# WBZ451 register map
Vendor: Microchip
Registers are 32-bit, read-write, reset 0x0 unless marked. A register's access mark holds for its fields unless they carry their own. Addresses are absolute, and some are shared; only a register's first bit layout is shown; [hi:lo] are bit positions; {n}, {i} and the like mark numbered series; 'fields as' and 'values as' point back to an identical list.

## SysTick
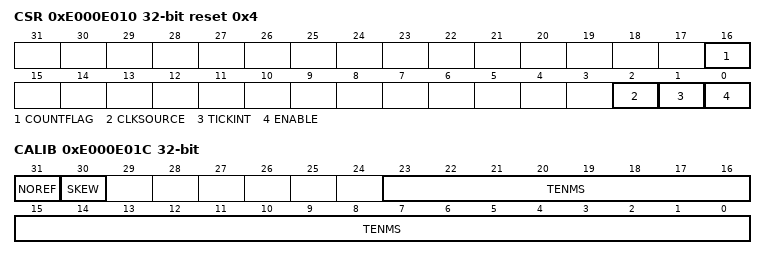
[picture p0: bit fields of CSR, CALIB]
0xE000E010 CSR reset 0x4
  [16] COUNTFLAG — Timer counted to 0 since last read of register
  [2] CLKSOURCE — Clock Source 0=external, 1=processor
    0=External clock; 1=Processor clock
  [1] TICKINT — SysTick Exception Request Enable
    0=Counting down to 0 does not assert the SysTick exception request; 1=Counting down to 0 asserts the SysTick exception request
  [0] ENABLE — SysTick Counter Enable
    0=Counter disabled; 1=Counter enabled
0xE000E014 RVR reset not defined
  [23:0] RELOAD — Value to load into the SysTick Current Value Register when the counter reaches 0
0xE000E018 CVR reset not defined
  [23:0] CURRENT — Current value at the time the register is accessed
0xE000E01C CALIB ro
  [31] NOREF — No Separate Reference Clock
    0=The reference clock is provided; 1=The reference clock is not provided
  [30] SKEW — TENMS is rounded from non-integer ratio
    0=10ms calibration value is exact; 1=10ms calibration value is inexact, because of the clock frequency
  [23:0] TENMS — Reload value to use for 10ms timing

## NVIC
{0xE000E100+4i} ISER{i} (i=0..4)
  [31:0] SETENA — Interrupt set enable bits
{0xE000E180+4i} ICER{i} (i=0..4)
  [31:0] CLRENA — Interrupt clear-enable bits
{0xE000E200+4i} ISPR{i} (i=0..4)
  [31:0] SETPEND — Interrupt set-pending bits
{0xE000E280+4i} ICPR{i} (i=0..4)
  [31:0] CLRPEND — Interrupt clear-pending bits
{0xE000E300+4i} IABR{i} (i=0..4)
  [31:0] ACTIVE — Interrupt active bits
{0xE000E400+i} IP{i} 8-bit (i=0..34)
  [2:0] PRI0 — Priority of interrupt n
0xE000EF00 STIR wo reset not defined
  [8:0] INTID — Interrupt ID to trigger

## MPU
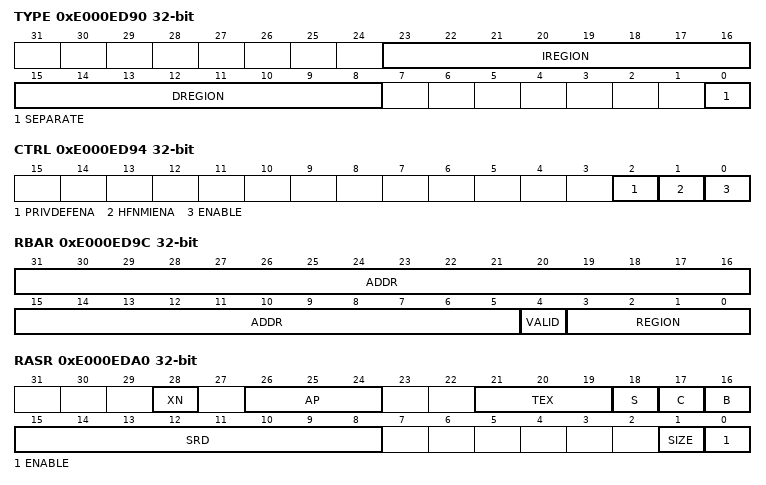
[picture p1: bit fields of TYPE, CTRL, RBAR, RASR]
0xE000ED90 TYPE ro reset not defined
  [23:16] IREGION — Number of Instruction Regions
  [15:8] DREGION — Number of Data Regions
  [0] SEPARATE — Separate instruction and Data Memory MapsRegions
0xE000ED94 CTRL reset not defined
  [2] PRIVDEFENA — Enables privileged software access to default memory map
  [1] HFNMIENA — Enable Hard Fault and NMI handlers
  [0] ENABLE — MPU Enable
0xE000ED98 RNR reset not defined
  [7:0] REGION — Region referenced by RBAR and RASR
0xE000ED9C RBAR reset not defined
  [31:5] ADDR — Region base address
  [4] VALID — Region number valid
  [3:0] REGION — Region number
0xE000EDA0 RASR reset not defined
  [28] XN — Execute Never Attribute
  [26:24] AP — Access Permission
  [21:19] TEX — TEX bit
  [18] S — Shareable bit
  [17] C — Cacheable bit
  [16] B — Bufferable bit
  [15:8] SRD — Sub-region disable
  [1] SIZE — Region Size
  [0] ENABLE — Region Enable
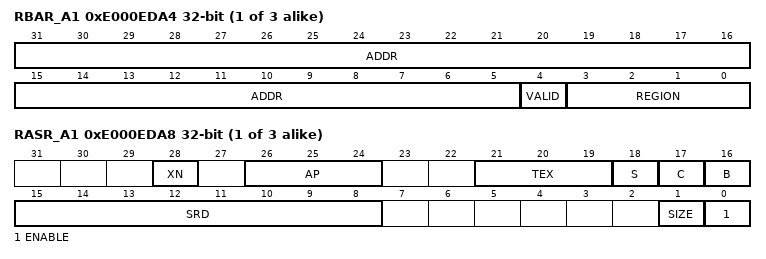
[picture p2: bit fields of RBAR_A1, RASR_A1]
{0xE000ED9C+8i} RBAR_A{i} reset not defined (i=1..3)
  fields as RBAR
{0xE000EDA0+8i} RASR_A{i} reset not defined (i=1..3)
  fields as RASR

## CoreDebug
0xE000EDF0 DHCSR reset not defined
  [25] S_RESET_ST, [24] S_RETIRE_ST, [19] S_LOCKUP, [18] S_SLEEP, [17] S_HALT, [31:16] DBGKEY, [5] C_SNAPSTALL, [3] C_MASKINTS, [2] C_STEP, [1] C_HALT, [0] C_DEBUGEN
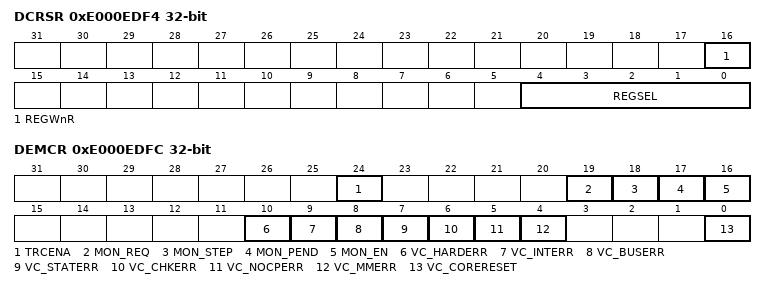
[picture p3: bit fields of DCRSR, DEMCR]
0xE000EDF4 DCRSR wo reset not defined
  [16] REGWnR, [4:0] REGSEL
0xE000EDF8 DCRDR reset not defined
0xE000EDFC DEMCR reset not defined
  [24] TRCENA, [19] MON_REQ, [18] MON_STEP, [17] MON_PEND, [16] MON_EN, [10] VC_HARDERR, [9] VC_INTERR, [8] VC_BUSERR, [7] VC_STATERR, [6] VC_CHKERR, [5] VC_NOCPERR, [4] VC_MMERR, [0] VC_CORERESET

## FPU
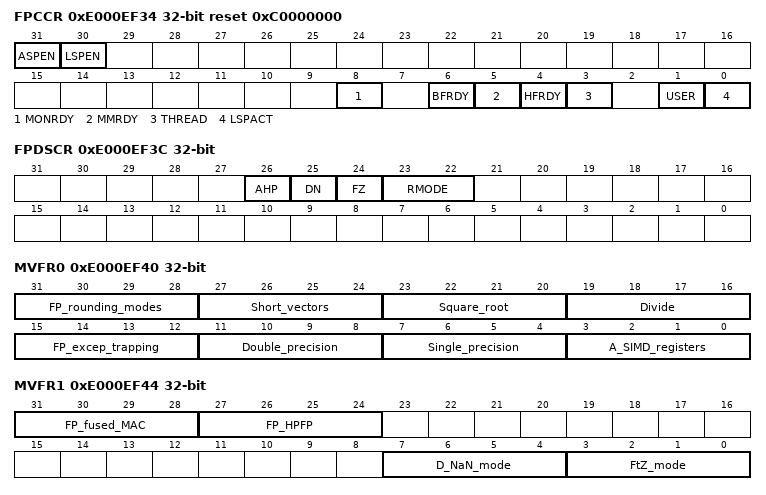
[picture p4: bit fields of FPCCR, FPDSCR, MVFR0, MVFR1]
0xE000EF34 FPCCR reset 0xC0000000
  [31] ASPEN, [30] LSPEN, [8] MONRDY, [6] BFRDY, [5] MMRDY, [4] HFRDY, [3] THREAD, [1] USER, [0] LSPACT
0xE000EF38 FPCAR reset not defined
  [31:3] ADDRESS — Address for FP registers in exception stack frame
0xE000EF3C FPDSCR
  [26] AHP — Default value for FPSCR.AHP
  [25] DN — Default value for FPSCR.DN
  [24] FZ — Default value for FPSCR.FZ
  [23:22] RMODE — Default value for FPSCR.RMODE
    0=RN (Round to Nearest); 1=RP (Round towards Positive Infinity); 2=RM (Round towards Negative Infinity); 3=RZ (Round towards Zero)
0xE000EF40 MVFR0 ro reset not defined
  [31:28] FP_rounding_modes, [27:24] Short_vectors, [23:20] Square_root, [19:16] Divide, [15:12] FP_excep_trapping, [11:8] Double_precision, [7:4] Single_precision, [3:0] A_SIMD_registers
0xE000EF44 MVFR1 ro reset not defined
  [31:28] FP_fused_MAC, [27:24] FP_HPFP, [7:4] D_NaN_mode, [3:0] FtZ_mode

## TPI
0xE0040000 SSPSR ro reset not defined
0xE0040004 CSPSR reset not defined
0xE0040010 ACPR reset not defined
  [12:0] PRESCALER
0xE00400F0 SPPR reset not defined
  [1:0] TXMODE
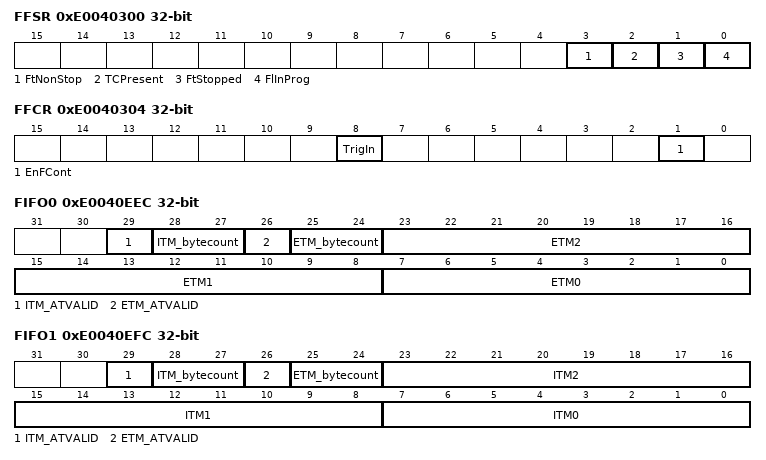
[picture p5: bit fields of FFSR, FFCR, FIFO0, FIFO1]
0xE0040300 FFSR ro reset not defined
  [3] FtNonStop, [2] TCPresent, [1] FtStopped, [0] FlInProg
0xE0040304 FFCR reset not defined
  [8] TrigIn, [1] EnFCont
0xE0040308 FSCR ro reset not defined
0xE0040EE8 TRIGGER ro reset not defined
  [0] TRIGGER
0xE0040EEC FIFO0 ro reset not defined
  [29] ITM_ATVALID, [28:27] ITM_bytecount, [26] ETM_ATVALID, [25:24] ETM_bytecount, [23:16] ETM2, [15:8] ETM1, [7:0] ETM0
0xE0040EF0 ITATBCTR2 ro reset not defined
  [0] ATREADY
0xE0040EF8 ITATBCTR0 ro reset not defined
  [0] ATREADY
0xE0040EFC FIFO1 ro reset not defined
  [29] ITM_ATVALID, [28:27] ITM_bytecount, [26] ETM_ATVALID, [25:24] ETM_bytecount, [23:16] ITM2, [15:8] ITM1, [7:0] ITM0
0xE0040F00 ITCTRL reset not defined
  [0] Mode
0xE0040FA0 CLAIMSET reset not defined
0xE0040FA4 CLAIMCLR reset not defined
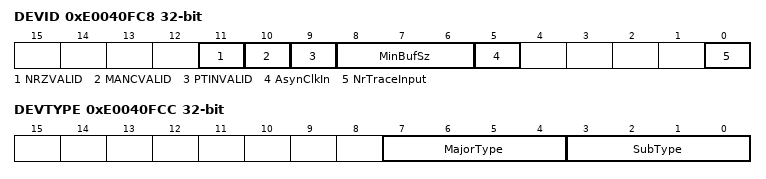
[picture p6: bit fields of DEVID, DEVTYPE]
0xE0040FC8 DEVID ro reset not defined
  [11] NRZVALID, [10] MANCVALID, [9] PTINVALID, [8:6] MinBufSz, [5] AsynClkIn, [0] NrTraceInput
0xE0040FCC DEVTYPE ro reset not defined
  [7:4] MajorType, [3:0] SubType

## ETM
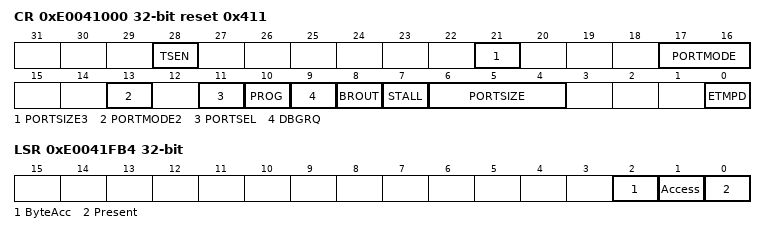
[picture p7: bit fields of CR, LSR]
0xE0041000 CR reset 0x411
  [28] TSEN — TimeStamp Enable
  [21] PORTSIZE3 — Port Size bit 3
  [17:16] PORTMODE — Port Mode bits 1:0
  [13] PORTMODE2 — Port Mode bit 2
  [11] PORTSEL — ETM Port Select
  [10] PROG — ETM Programming
  [9] DBGRQ — Debug Request Control
  [8] BROUT — Branch Output
  [7] STALL — Stall Processor
  [6:4] PORTSIZE — Port Size bits 2:0
  [0] ETMPD — ETM Power Down
0xE0041004 CCR ro reset 0x8C802000
0xE0041008 TRIGGER reset not defined
0xE0041010 SR reset not defined
0xE0041014 SCR ro reset 0x20D09
0xE0041020 TEEVR reset not defined
0xE0041024 TECR1 reset not defined
0xE0041028 FFLR reset not defined
0xE0041140 CNTRLDVR1 reset not defined
0xE00411E0 SYNCFR ro reset 0x400
0xE00411E4 IDR ro reset 0x4114F250
0xE00411E8 CCER ro reset 0x18541800
0xE00411F0 TESSEICR reset not defined
0xE00411F8 TSEVT reset not defined
0xE0041200 TRACEIDR
0xE0041208 IDR2 ro
0xE0041314 PDSR ro reset 0x1
0xE0041EE0 ITMISCIN ro reset not defined
0xE0041EE8 ITTRIGOUT wo reset not defined
0xE0041EF0 ITATBCTR2 ro reset not defined
0xE0041EF8 ITATBCTR0 wo reset not defined
0xE0041F00 ITCTRL
  [0] INTEGRATION
0xE0041FA0 CLAIMSET reset not defined
0xE0041FA4 CLAIMCLR reset not defined
0xE0041FB0 LAR wo reset not defined
0xE0041FB4 LSR ro reset not defined
  [2] ByteAcc, [1] Access, [0] Present
0xE0041FB8 AUTHSTATUS ro reset not defined
0xE0041FCC DEVTYPE ro reset 0x13
0xE0041FD0 PIDR4 ro reset 0x4
{0xE0041FC0+4i} PIDR{i} ro (i=5..7)
0xE0041FE0 PIDR0 ro reset 0x25
0xE0041FE4 PIDR1 ro reset 0xB9
0xE0041FE8 PIDR2 ro reset 0xB
0xE0041FEC PIDR3 ro
0xE0041FF0 CIDR0 ro reset 0xD
0xE0041FF4 CIDR1 ro reset 0x90
0xE0041FF8 CIDR2 ro reset 0x5
0xE0041FFC CIDR3 ro reset 0xB1
